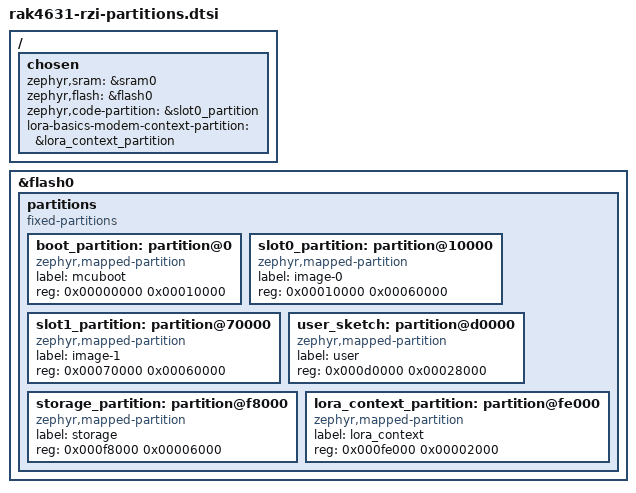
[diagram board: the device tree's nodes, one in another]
/* SPDX-FileCopyrightText: Copyright (c) 2026 RAKwireless */
/* SPDX-License-Identifier: Apache-2.0 */
/*
 * rak4631/nrf52840/rzi flash map (nRF52840, 1 MB).
 * Boot and both slots match upstream Zephyr rak4631.dts. An Arduino
 * loader and an RZI application replace each other in slot0, so the
 * rzi snippet must keep this map. The upstream 192 KB storage region
 * holds the Arduino LLEXT, Zephyr settings, and the LoRa Basics Modem
 * context. Native Zephyr apps ignore user_sketch. Settings and the
 * modem context do not share a partition.
 *
 * 64K boot + 384K slot0 + 384K slot1 + 160K sketch + 24K storage + 8K context.
 */

/ {
	chosen {
		zephyr,sram = &sram0;
		zephyr,flash = &flash0;
		zephyr,code-partition = &slot0_partition;
		lora-basics-modem-context-partition = &lora_context_partition;
	};
};

&flash0 {
	partitions {
		compatible = "fixed-partitions";
		ranges;
		#address-cells = <1>;
		#size-cells = <1>;

		boot_partition: partition@0 {
			compatible = "zephyr,mapped-partition";
			label = "mcuboot";
			reg = <0x00000000 0x00010000>;
		};

		slot0_partition: partition@10000 {
			compatible = "zephyr,mapped-partition";
			label = "image-0";
			reg = <0x00010000 0x00060000>;
		};

		slot1_partition: partition@70000 {
			compatible = "zephyr,mapped-partition";
			label = "image-1";
			reg = <0x00070000 0x00060000>;
		};

		user_sketch: partition@d0000 {
			compatible = "zephyr,mapped-partition";
			label = "user";
			reg = <0x000d0000 0x00028000>;
		};

		storage_partition: partition@f8000 {
			compatible = "zephyr,mapped-partition";
			label = "storage";
			reg = <0x000f8000 0x00006000>;
		};

		lora_context_partition: partition@fe000 {
			compatible = "zephyr,mapped-partition";
			label = "lora_context";
			reg = <0x000fe000 0x00002000>;
		};
	};
};
